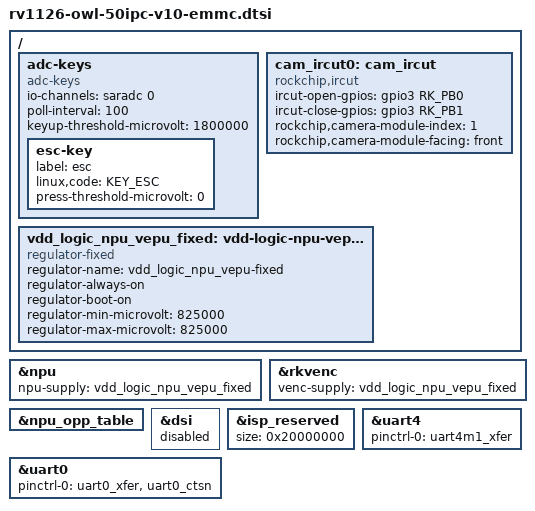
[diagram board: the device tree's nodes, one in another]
// SPDX-License-Identifier: (GPL-2.0+ OR MIT)
/*
 * Copyright (c) 2020 Rockchip Electronics Co., Ltd.
 */

/dts-v1/;
#include "rv1126.dtsi"
#include "rv1126-owl-discrete-dcdc.dtsi"
#include <dt-bindings/input/input.h>

/ {
	adc-keys {
		compatible = "adc-keys";
		io-channels = <&saradc 0>;
		io-channel-names = "buttons";
		poll-interval = <100>;
		keyup-threshold-microvolt = <1800000>;

		esc-key {
			label = "esc";
			linux,code = <KEY_ESC>;
			press-threshold-microvolt = <0>;
		};
	};

	cam_ircut0: cam_ircut {
		status = "okay";
		compatible = "rockchip,ircut";
		ircut-open-gpios = <&gpio3 RK_PB0 GPIO_ACTIVE_HIGH>;
		ircut-close-gpios  = <&gpio3 RK_PB1 GPIO_ACTIVE_HIGH>;
		rockchip,camera-module-index = <1>;
		rockchip,camera-module-facing = "front";
	};

    /delete-node/ vdd-vepu;

    vdd_logic_npu_vepu_fixed: vdd-logic-npu-vepu-fixed {
        compatible = "regulator-fixed";
        regulator-name = "vdd_logic_npu_vepu-fixed";
        regulator-always-on;
        regulator-boot-on;
        regulator-min-microvolt = <825000>;
        regulator-max-microvolt = <825000>;
    };
};

&npu {
    status = "okay";
    npu-supply = <&vdd_logic_npu_vepu_fixed>;
};

&rkvenc {
    status = "okay";
    venc-supply = <&vdd_logic_npu_vepu_fixed>;
};

&npu_opp_table {
 /delete-node/ opp-700000000;
 /delete-node/ opp-800000000;
 /delete-node/ opp-934000000;
};

&dsi {
    status = "disabled";
};

&isp_reserved {
    size = <0x20000000>;
};

&uart0 {
    pinctrl-names = "default";
    pinctrl-0 = <&uart0_xfer &uart0_ctsn>;
    dma-names = "tx", "rx";
    status = "okay";
};

&uart4 {
    status = "okay";
    pinctrl-names = "default";
    dma-names = "tx", "rx";
    pinctrl-0 = <&uart4m1_xfer>;
};
